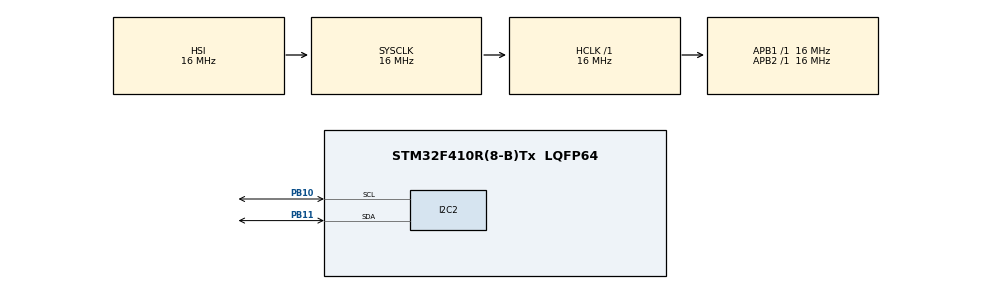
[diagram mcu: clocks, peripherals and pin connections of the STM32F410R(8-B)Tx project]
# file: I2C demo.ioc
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Mcu.Family=STM32F4
Mcu.Name=STM32F410R(8-B)Tx
Mcu.Package=LQFP64
NVIC.PriorityGroup=NVIC_PRIORITYGROUP_4
PB10.Mode=I2C
PB10.Signal=I2C2_SCL
PB11.Mode=I2C
PB11.Signal=I2C2_SDA
ProjectManager.HeapSize=0x200
ProjectManager.StackSize=0x400
ProjectManager.TargetToolchain=STM32CubeIDE
RCC.AHBFreq_Value=16000000
RCC.APB1Freq_Value=16000000
RCC.APB2Freq_Value=16000000
RCC.CortexFreq_Value=16000000
RCC.HSE_VALUE=25000000
RCC.HSI_VALUE=16000000
RCC.LSE_VALUE=32768
RCC.SYSCLKFreq_VALUE=16000000
RCC.VCOOutputFreq_Value=192000000
board=custom

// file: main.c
/* USER CODE BEGIN Header */
/**
  ******************************************************************************
  * @file           : main.c
  * @brief          : Main program body
  ******************************************************************************
  * @attention
  *
  * Copyright (c) 2026 STMicroelectronics.
  * All rights reserved.
  *
  * This software is licensed under terms that can be found in the LICENSE file
  * in the root directory of this software component.
  * If no LICENSE file comes with this software, it is provided AS-IS.
  *
  ******************************************************************************
  */
/* USER CODE END Header */
#include "main.h"

#define MPU6050_ADDR (0x68<<1)
#define PWR_MGMT_1 0x6B
#define ACCL_START 0x3B

/* USER CODE BEGIN Includes */
uint8_t raw_data[14];

/* USER CODE END Includes */

I2C_HandleTypeDef hi2c2;

void SystemClock_Config(void);
static void MX_GPIO_Init(void);
static void MX_I2C2_Init(void);

/* USER CODE BEGIN 0 */
int wake_up_mpu(void){
	uint8_t wake = 0x00;
	HAL_I2C_Mem_Write(&hi2c2, MPU6050_ADDR, PWR_MGMT_1, 1, &wake, 1, 100);
}

int read_raw_data(void){
	HAL_I2C_Mem_Read(&hi2c2, MPU6050_ADDR, ACCL_START, 1, raw_data, 14, 100);
}

/* USER CODE END 0 */

int main(void)
{

  /* MCU Configuration--------------------------------------------------------*/

  /* Reset of all peripherals, Initializes the Flash interface and the Systick. */
  HAL_Init();

  /* Configure the system clock */
  SystemClock_Config();

  /* Initialize all configured peripherals */
  MX_GPIO_Init();
  MX_I2C2_Init();
  /* USER CODE BEGIN 2 */
  wake_up_mpu();
  read_raw_data();

  /* USER CODE END 2 */

  /* Infinite loop */
  while (1)
  {

  }
}

void SystemClock_Config(void)
{
  RCC_OscInitTypeDef RCC_OscInitStruct = {0};
  RCC_ClkInitTypeDef RCC_ClkInitStruct = {0};

  /** Configure the main internal regulator output voltage
  */
  __HAL_RCC_PWR_CLK_ENABLE();
  __HAL_PWR_VOLTAGESCALING_CONFIG(PWR_REGULATOR_VOLTAGE_SCALE1);

  /** Initializes the RCC Oscillators according to the specified parameters
  * in the RCC_OscInitTypeDef structure.
  */
  RCC_OscInitStruct.OscillatorType = RCC_OSCILLATORTYPE_HSI;
  RCC_OscInitStruct.HSIState = RCC_HSI_ON;
  RCC_OscInitStruct.HSICalibrationValue = RCC_HSICALIBRATION_DEFAULT;
  RCC_OscInitStruct.PLL.PLLState = RCC_PLL_NONE;
  if (HAL_RCC_OscConfig(&RCC_OscInitStruct) != HAL_OK)
  {
    Error_Handler();
  }

  /** Initializes the CPU, AHB and APB buses clocks
  */
  RCC_ClkInitStruct.ClockType = RCC_CLOCKTYPE_HCLK|RCC_CLOCKTYPE_SYSCLK
                              |RCC_CLOCKTYPE_PCLK1|RCC_CLOCKTYPE_PCLK2;
  RCC_ClkInitStruct.SYSCLKSource = RCC_SYSCLKSOURCE_HSI;
  RCC_ClkInitStruct.AHBCLKDivider = RCC_SYSCLK_DIV1;
  RCC_ClkInitStruct.APB1CLKDivider = RCC_HCLK_DIV1;
  RCC_ClkInitStruct.APB2CLKDivider = RCC_HCLK_DIV1;

  if (HAL_RCC_ClockConfig(&RCC_ClkInitStruct, FLASH_LATENCY_0) != HAL_OK)
  {
    Error_Handler();
  }
}

static void MX_I2C2_Init(void)
{

  hi2c2.Instance = I2C2;
  hi2c2.Init.ClockSpeed = 100000;
  hi2c2.Init.DutyCycle = I2C_DUTYCYCLE_2;
  hi2c2.Init.OwnAddress1 = 0;
  hi2c2.Init.AddressingMode = I2C_ADDRESSINGMODE_7BIT;
  hi2c2.Init.DualAddressMode = I2C_DUALADDRESS_DISABLE;
  hi2c2.Init.OwnAddress2 = 0;
  hi2c2.Init.GeneralCallMode = I2C_GENERALCALL_DISABLE;
  hi2c2.Init.NoStretchMode = I2C_NOSTRETCH_DISABLE;
  if (HAL_I2C_Init(&hi2c2) != HAL_OK)
  {
    Error_Handler();
  }

}

static void MX_GPIO_Init(void)
{

  /* GPIO Ports Clock Enable */
  __HAL_RCC_GPIOB_CLK_ENABLE();

}

void Error_Handler(void)
{
  __disable_irq();
  while (1)
  {
  }
}
